# SGX530 register map
Vendor: Texas Instruments
Registers are 32-bit, read-write, no defined reset value unless marked. A register's access mark holds for its fields unless they carry their own. Offsets are as the file gives them; [hi:lo] are bit positions; {n}, {i} and the like mark numbered series; 'fields as' and 'values as' point back to an identical list.

## SGX530 (part 2 of 2)
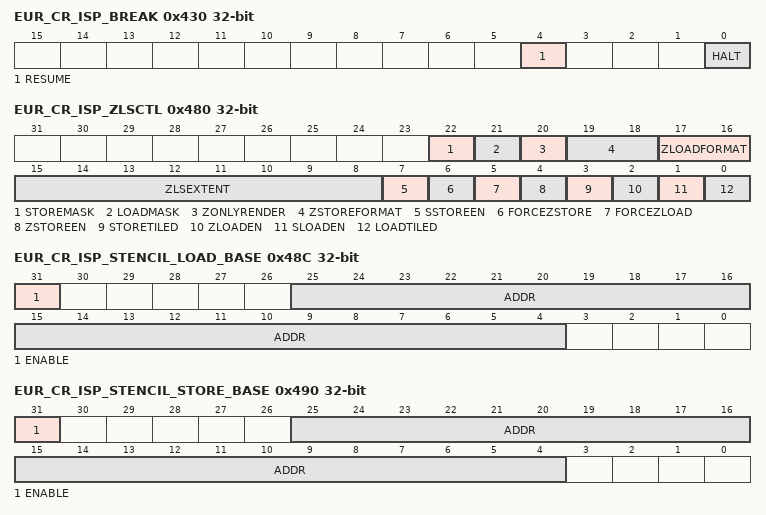
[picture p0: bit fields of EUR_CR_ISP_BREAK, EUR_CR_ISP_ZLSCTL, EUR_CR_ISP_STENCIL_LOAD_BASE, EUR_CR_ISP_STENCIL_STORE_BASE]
0x430 EUR_CR_ISP_BREAK wo — Object breakpoints can be inserted by the driver to interrupt a render part way and then resume the render from the point of interrupt at a later time, this register controls what happens when a breakpoint has been encountered.
  [4] RESUME — Resumes the current render after a breakpoint object is encountered in the internal parameter stream
  [0] HALT — Terminates the current render after a breakpoint object is encountered in the internal parameter stream
0x434 EUR_CR_ISP_3DCONTEXT wo
  [0] ENABLE — ISP Context Store, any write to this register will cause the ISP to halt processing new primitives, insert an end of render command and wait for the current primitives in the pipeline to complete processing up to the inserted end of render.
0x438 EUR_CR_ISP_FPU ro
  [31:0] SIGNATURE — ISP FPU signature result. A signature is an accumulative LFSR (Linear Feedback Shift Register) of the valid pipeline data using an XOR structure.
0x43C EUR_CR_TSP_PARAMETER_CACHE wo
  [0] INVALIDATE — Any write to this register will invalidate the Content Addressable Memory in the TSP parameter fetch cache
0x440 EUR_CR_TSP_PARAMETER_FETCH
  [1:0] TTE_SCALE — Scale factor for TSP parameter fetch to BIF TTE.
0x480 EUR_CR_ISP_ZLSCTL — Image Synthesis Processor Z Load/Store & format global control register
  [22] STOREMASK — This bit modifies the behaviour when ISP_ZLSCTL:[ZSTOREFORMAT] = 0x0. 0 - Binary 0 is stored in place of the current rendered mask plane. All stored Z values will appear in memory as positive IEEE floats; 1 - The mask plane is stored per pixel location a rendered to the on-chip tile buffer and occupies the MSB (sign bit) of all IEEE float dwords
  [21] LOADMASK — This bit modifies the behaviour when ISP_ZLSCTL:[ZLOADFORMAT] = 0x0. 0 - The entire tile will be loaded with the mask plane value as determined by ISP_BGOBJ:[MASK]; 1 - The mask plane is loaded exactly as it appears in memory with the mask plane bit in the MSB (sign bit) of each loaded IEEE float formatted dword
  [20] ZONLYRENDER — When set, only the Z buffer is rendered. Opaque and translucent objects are stencil and depth tested as usual but no pixel spans are emitted to the PDS Pixel presenter. Pixels within punch through and depth feedback objects are emitted on their first pass as a result of passing the up-front depth test by default. However, on their feedback depth test, these pixels will not be output regardless of the depth test result. The intention is to calculate a scene Z buffer without doing any further rendering.
  [19:18] ZSTOREFORMAT — Selects the format depth, stencil and viewport is stored in: 0x0 32 bit IEEE SP Float; 0x1 24 bit Integer + 8-bit Stencil; 0x2 Two 16 bit Integers (Packed format); 0x3 32-bit IEEE Float 8-bit Stencil 1-bit Viewport Compressed, addressed using DPM
  [17:16] ZLOADFORMAT — Selects the format depth, stencil and viewport is stored in: 0x0 32 bit IEEE SP Float; 0x1 24 bit Integer + 8-bit Stencil; 0x2 Two 16 bit Integers (Packed format); 0x3 32-bit IEEE Float 8-bit Stencil 1-bit Viewport Compressed, addressed using DPM
  [15:8] ZLSEXTENT — Display width in tiles (16 pixels) minus one: 0x00 1 tile (16 pixels) 0x01 2 tiles (32 pixels) .. 0xFF 256 tiles (4096 pixels)
  [7] SSTOREEN — When set to 1, if the ZSTORE bit in the region header is also set then the stencil buffer is stored to memory after each tile is processed
  [6] FORCEZSTORE — If set to 1 the depth/stencil buffer is always stored at the end of each tile irrespective of the region header ZSTORE bit.
  [5] FORCEZLOAD — If set to 1 the depth/stencil buffer is always loaded at the start of each tile irrespective of the region header ZLOAD bit.
  [4] ZSTOREEN — When set to 1, if the ZSTORE bit in the region header is also set then the depth buffer is stored to memory after each tile is processed
  [3] STORETILED — When set to 1 depth and stencil data is written out in "Tiled" order. (Note: Data can not be written as tiled, if the ZSTOREFORMAT = 0x3. In this case STORETILED should be set to ‘0’)
  [2] ZLOADEN — When set to 1, if the ZLOAD bit in the region header is also set then the depth buffer is read from memory prior to tile processing
  [1] SLOADEN — When set to 1, if the ZLOAD bit in the region header is also set then the stencil buffer is read from memory prior to tile processing
  [0] LOADTILED — When set to 1 depth, stencil data is loaded in "Tiled" order (Note: Data can not be read as tiled, if the ZSTOREFORMAT = 0x3. In this case LOADTILED should be set to ‘0’)
0x484 EUR_CR_ISP_ZLOAD_BASE — This register defines the base address in memory of the Z Buffer base address to load into the ISP for non-compressed ZLS formats.
  [25:4] ADDR — 64MB Addressable, 16byte aligned Base Address of the Z Buffer Load base address
0x488 EUR_CR_ISP_ZSTORE_BASE — This register defines the base address in memory of the Z Buffer base address to store data from the ISP for non-compressed ZLS formats.
  fields as EUR_CR_ISP_ZLOAD_BASE
0x48C EUR_CR_ISP_STENCIL_LOAD_BASE — This register defines the base address in memory of the Stencil Buffer base address to load into the ISP for Int24 and IEEE ZLS formats. This alternate stencil buffer base address is selectable based on the enable bit.
  [31] ENABLE — When set to 1, enables fetching of stencil from a separate base address
  [25:4] ADDR — 64MB Addressable, 16byte aligned Base Address of the Stencil Buffer Load base address
0x490 EUR_CR_ISP_STENCIL_STORE_BASE — This register defines the base address in memory of the Stencil Buffer base address to store data from the ISP for Int24 and IEEE ZLS formats. This alternate stencil buffer base address is selectable based on the enable bit.
  [31] ENABLE — When set to 1, enables saving of stencil to a separate base address
  [25:4] ADDR — 64MB Addressable, 16byte aligned Base Address of the Stencil Buffer Load base address
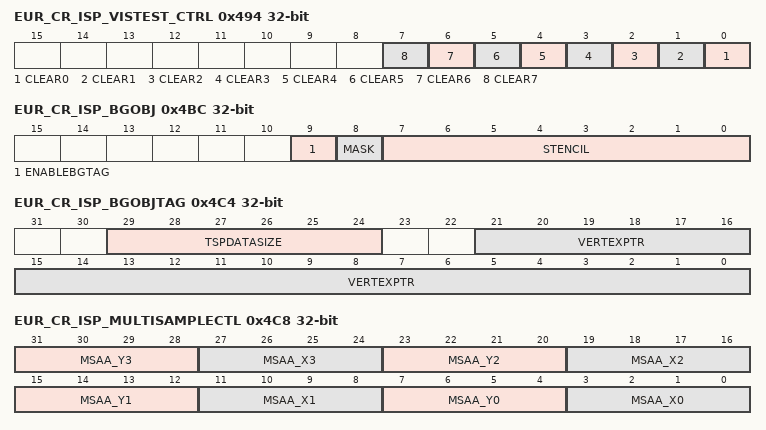
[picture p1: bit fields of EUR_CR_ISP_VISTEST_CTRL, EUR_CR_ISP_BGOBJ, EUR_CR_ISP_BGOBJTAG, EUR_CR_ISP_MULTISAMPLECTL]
0x494 EUR_CR_ISP_VISTEST_CTRL wo — This register can be used to reset the results of the 8 visibility test results. Write a 1 to the required bit field to clear the result register
  [n] CLEAR{n} (n=0..7) — Resets Visibility Test register {n}
{0x498+4i} EUR_CR_ISP_VISTEST_VISIBLE{i} ro (i=0..7)
  [31:0] COUNT — Visibility Test counter {i}
0x4B8 EUR_CR_ISP_BGOBJDEPTH — The ISP operates by comparing depth values of incoming objects with the results of previous depth compares, in order to make sure there are no un-initialised values at the start of the tile or to cover pixels where there are no objects in the scene a default background object is configured under register control. This register provides the floating point depth value for this background object.
  [31:0] VALUE — Hardware background object depth value in 32 bit IEEE single precision floating point format
0x4BC EUR_CR_ISP_BGOBJ — The ISP operates by comparing depth values of incoming objects with the results of previous depth compares, in order to make sure there is no un-initialised values at the start of the tile or to cover pixels where there are no objects in the scene a default background object is configured under register control. This register provides tag, mask and stencil information for this background object.
  [9] ENABLEBGTAG — When set to 1, at the start of each tile the ISP tag buffer is initialised with the background object tag (default = 1)
  [8] MASK — Hardware background object mask plane
  [7:0] STENCIL — Hardware background object stencil
0x4C4 EUR_CR_ISP_BGOBJTAG — The ISP operates by comparing depth values of incoming objects with the results of previous depth compares, in order to make sure there are no unitialised values at the start of the tile or to cover pixels where there are no objects in the scene a default background object is configured under register control. This register provides TSP and Vertex information for this background object.
  [29:24] TSPDATASIZE — Hardware background object TSP data size in dwords
  [21:0] VERTEXPTR — Bits 25:4 of the hardware background object vertex pointer (64MB range on 16 byte boundaries)
0x4C8 EUR_CR_ISP_MULTISAMPLECTL — This applies when anti-aliasing is enabled. This is used by the ISP to adjust the sample positions.
  [31:28] MSAA_Y3 — Unsigned sub-pixel offset for the 4th multisample Y position
  [27:24] MSAA_X3 — Unsigned sub-pixel offset for the 4th multisample X position
  [23:20] MSAA_Y2 — Unsigned sub-pixel offset for the 3rd multisample Y position
  [19:16] MSAA_X2 — Unsigned sub-pixel offset for the 3rd multisample X position
  [15:12] MSAA_Y1 — Unsigned sub-pixel offset for the 2nd multisample Y position
  [11:8] MSAA_X1 — Unsigned sub-pixel offset for the 2nd multisample X position
  [7:4] MSAA_Y0 — Unsigned sub-pixel offset for the 1st multisample Y position
  [3:0] MSAA_X0 — Unsigned sub-pixel offset for the 1st multisample X position
0x4CC EUR_CR_ISP_SIG1 ro
  [31:0] PRECALC — Signature analysis - face equation precalc. A signature is an accumulative LFSR (Linear Feedback Shift Register) of the valid pipeline data using an XOR structure.
0x4D0 EUR_CR_ISP_SIG2 ro
  [31:0] EDGE — Signature analysis - edge processors. A signature is an accumulative LFSR (Linear Feedback Shift Register) of the valid pipeline data using an XOR structure.
0x4D4 EUR_CR_ISP_SIG3 ro
  [31:0] TAGWRITE — Signature analysis - state buffer storage. A signature is an accumulative LFSR (Linear Feedback Shift Register) of the valid pipeline data using an XOR structure.
0x4D8 EUR_CR_ISP_SIG4 ro
  [31:0] SPAN — Signature analysis - spans to PDS pixel presenter. A signature is an accumulative LFSR (Linear Feedback Shift Register) of the valid pipeline data using an XOR structure.
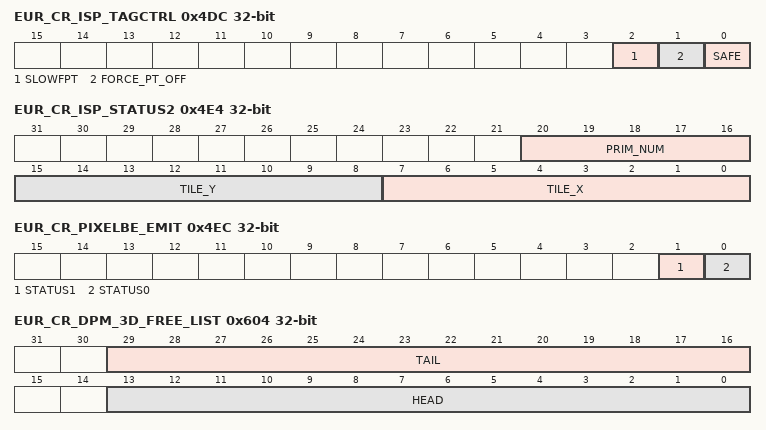
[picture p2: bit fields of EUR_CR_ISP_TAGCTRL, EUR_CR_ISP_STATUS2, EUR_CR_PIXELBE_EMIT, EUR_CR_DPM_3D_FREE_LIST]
0x4DC EUR_CR_ISP_TAGCTRL
  [2] SLOWFPT — Debug punchthrough, converts fast punchthrough to normal punchthrough
  [1] FORCE_PT_OFF — Debug punchthrough mode which forces pt_off after every pt,dfb and fpt triangle
  [0] SAFE — Safe flush mode, pass-spawn flushes for every translucent object
0x4E0 EUR_CR_ISP_STATUS1 ro
  [25:2] CTRL_STREAM_POS — Control Stream Position after context switch
0x4E4 EUR_CR_ISP_STATUS2 ro
  [20:16] PRIM_NUM — Position of current primitive after context switch
  [15:8] TILE_Y — Tile Y coordinate after context switch
  [7:0] TILE_X — Tile X coordinate after context switch
0x4E8 EUR_CR_ISP_DEPTHSORT
  [0] DETERMINISTIC — deterministic mode for depth sorter
0x4EC EUR_CR_PIXELBE_EMIT ro — This register indicates if the PixelBE would stall the USE if there were another emit. '1' indicates that the PixelBE would stall the USE. '0' indicates that the PixelBE would not stall the USE.
  [1] STATUS1 — Pipe 1 status
  [0] STATUS0 — Pipe 0 status
0x600 EUR_CR_DPM_3D_PAGE_TABLE_BASE — Effective on load 3D context, this register defines the base address of the page table being referenced in the process of de-allocating pages during a 3D render.
  [27:4] ADDR — 256MB Addressable, 16Byte aligned Base Address for 3D context page tables in the DPM module
0x604 EUR_CR_DPM_3D_FREE_LIST — Between the FREE_LIST_HEAD and FREE_LIST_TAIL there must be a valid chain of linked pages. The linked list is stored in memory, at the EUR_CR_DPM_3D_PAGE_TABLE_BASE_ADDRESS and is effective on load 3D context.
  [29:16] TAIL — This register defines the last page to be used for the 3D page allocation, on a load 3D context. (The tail of the free list.)
  [13:0] HEAD — This register defines the first page to be used for the 3D page allocation, on a load 3D context.
0x614 EUR_CR_DPM_PDS_PAGE_THRESHOLD — This is the threshold in 4KB pages at which the hardware will stop double buffering the internal vertex processing buffers (and drop to single buffered mode). This is required in order to guarantee that a 3D render can run when running in dynamic parameter management mode. It should be set to 0.25MB less (in pages 0x40) than the ZLS threshold (or 0 in very small memory systems).
  [13:0] VALUE — Page Threshold at which vertex buffers stop being double buffered
0x618 EUR_CR_DPM_TA_ALLOC_PAGE_TABLE_BASE — Effective on Loading the TA Page Table Context, this register defines the base address of the page table being referenced in the process of allocating pages by the TE and MTE.
  [27:4] ADDR — 256MB Addressable, 16Byte aligned Base Address for TE/MTE context page tables in the DPM module.
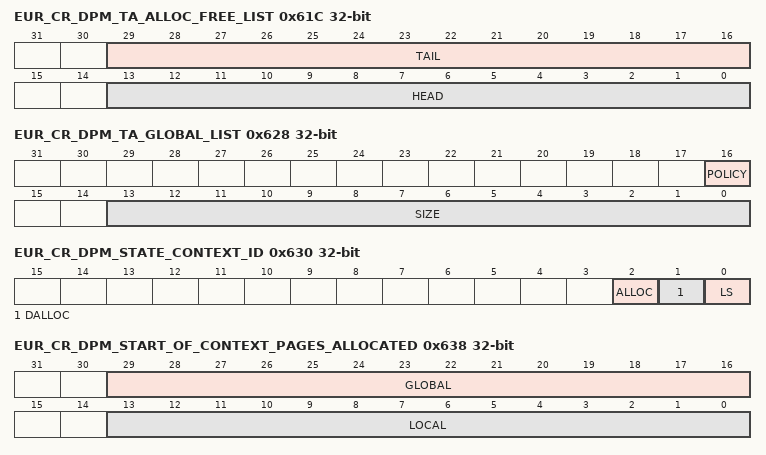
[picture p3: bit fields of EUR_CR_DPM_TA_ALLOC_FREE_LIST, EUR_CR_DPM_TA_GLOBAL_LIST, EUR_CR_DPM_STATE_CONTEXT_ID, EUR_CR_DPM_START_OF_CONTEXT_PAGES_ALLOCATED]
0x61C EUR_CR_DPM_TA_ALLOC_FREE_LIST — Between the FREE_LIST_HEAD and FREE_LIST_TAIL there must be a valid chain of linked pages. The linked list is stored in memory, at the EUR_CR_DPM_TA_ALLOC_PAGE_TABLE_BASE_ADDRESS and is effective on Loading the TA Page Table Context.
  [29:16] TAIL — This register defines the last page for the free list manipulated during TE and MTE page allocation
  [13:0] HEAD — This register defines the start page for the free list manipulated during TE and MTE page allocation
0x620 EUR_CR_DPM_TA_PAGE_THRESHOLD
  [13:0] VALUE — Effective on Loading the TA Page Table Context, the maximum number of pages to allocate before signaling almost out of memory.
0x624 EUR_CR_DPM_ZLS_PAGE_THRESHOLD
  [13:0] VALUE — Effective on Loading the TA Page Table Context, the maximum number of pages to allocate before signaling out of memory to the host. The ZLS threshold should be set such that sufficient pages are left available to the ZLS module when it performs its dynamic memory allocation upon a partial render. The number of pages spare should be set to be larger than the maximum pages for 1 macro tile of Z data. For example: If 4 pages are required for 1 macro tile of Z, and there are 50 pages in the system, then this threshold should be set to 50 - 4 = 46.
0x628 EUR_CR_DPM_TA_GLOBAL_LIST
  [16] POLICY — Effective on Loading the TA Page Table Context, a value of 1 in this field enables the global list size limit
  [13:0] SIZE — Effective on Loading the TA Page Table Context, the maximum number of pages to allocate to the global list before signaling global list out of memory.
0x62C EUR_CR_DPM_STATE_TABLE_BASE — Effective immediately, this register defines the base address of the state table when it is read and written to/from memory. The state table itself contains the head, tail and number of pages allocated to every macrotile, and the global list. Each context needs a separate state page table.
  [27:4] ADDR — 256MB Addressable, 16Byte aligned Base Address for State Table in the DPM module.
0x630 EUR_CR_DPM_STATE_CONTEXT_ID
  [2] ALLOC — Effective immediately, this field defines the which of the internal contexts is to be used for allocating memory
  [1] DALLOC — Effective immediately, this field defines the which of the internal contexts is to be used for de-allocating memory
  [0] LS — Effective immediately, this field defines which of the internal contexts is to be loaded or stored from/to memory
0x634 EUR_CR_DPM_CONTROL_TABLE_BASE — Effective immediately, this register defines the base address of the control table when it is read and written to/from memory. The control table itself contains the current offset into the page, and whether a page has been allocated, for each macrotile. Each context needs a separate state page table.
  [27:4] ADDR — 256MB Addressable, 16Byte aligned Base Address for the Control Table in the DPM module.
0x638 EUR_CR_DPM_START_OF_CONTEXT_PAGES_ALLOCATED
  [29:16] GLOBAL — Effective on the loading of the TA Page Table Context, this register defines the number of the pages which are currently allocated to the context global list. The value for this register is read from the matching status register, on a context store, and loaded on a context load.
  [13:0] LOCAL — Effective on the loading of the TA Page Table Context, this register defines the number of the pages which are currently allocated to the context. The value for this register is read from the matching status register, on a context store, and loaded on a context load.
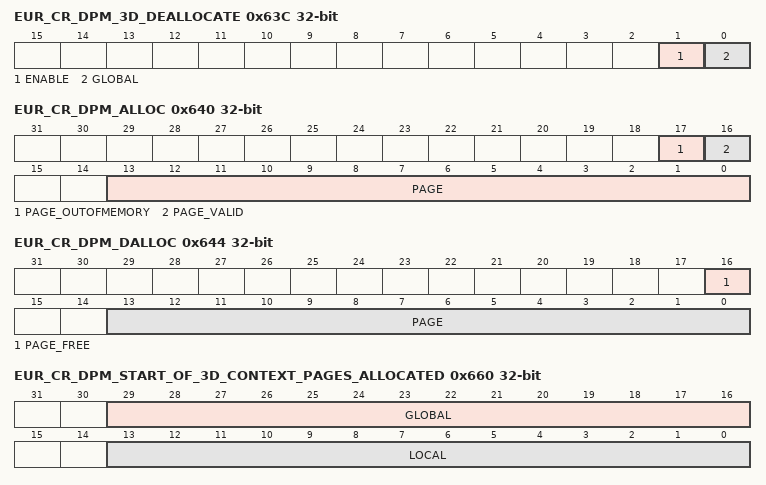
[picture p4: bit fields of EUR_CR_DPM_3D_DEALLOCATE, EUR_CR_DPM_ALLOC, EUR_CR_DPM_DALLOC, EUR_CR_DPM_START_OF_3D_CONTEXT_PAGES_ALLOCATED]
0x63C EUR_CR_DPM_3D_DEALLOCATE
  [1] ENABLE — Effective on start render, this field indicates that the hardware should de-allocate Effective on start render, this field indicates that the hardware should de-allocate memory.mory.
  [0] GLOBAL — Effective on start render, this field indicates that the hardware should de-allocate the memory associated with the global list if it is set.
0x640 EUR_CR_DPM_ALLOC — A write to this register invalidates the current contents and causes a new allocation cycle
  [17] PAGE_OUTOFMEMORY — Out of memory. Indicates that the action is pending due to an out of memory condition.
  [16] PAGE_VALID — On a read a value of 1 in this field indicates that the page has been allocated, and that the page is valid.
  [13:0] PAGE — A read of this register returns the page allocated to the host, when valid. If it is not valid the return data is undefined.
0x644 EUR_CR_DPM_DALLOC — A write to this register invalidates the current contents and causes a new de-allocation cycle
  [16] PAGE_FREE — A read indicates whether the page has been freed
  [13:0] PAGE — The page to be de-allocated by the hardware
0x648 EUR_CR_DPM_TA_ALLOC
  [29:16] FREE_LIST_PREVIOUS — Effective on Load TA Page Table Context: TA Alloc Free List Previous Page. The DPM maintains the previous and current free list pointers. On a context load this value must be loaded in. For the initial case it should be set to the penultimate page after initialisation (normally TAIL - 1).
0x64C EUR_CR_DPM_3D
  [29:16] FREE_LIST_PREVIOUS — Effective on Load 3D Page Table Context: 3D Free List Previous Page. The DPM maintains the previous and current free list pointers. On a context load this value must be loaded in. For the initial case it should be set to the penultimate page after initialisation (normally TAIL - 1).
0x658 EUR_CR_DPM_PARTIAL_RENDER
  [0] ENABLE — Once The TA DPM has run out of memory, and the driver has scheduled an abort, there must be a partial render performed on the context in order to free memory. This bit is set before the partial render is started.
0x65C EUR_CR_DPM_LSS_PARTIAL_CONTEXT
  [0] OPERATION — When set indicates that on a Context state table load, reset or store only the best macro tile, rather than the full scene.
0x660 EUR_CR_DPM_START_OF_3D_CONTEXT_PAGES_ALLOCATED
  [29:16] GLOBAL — Effective on the loading of the 3D Page Table Context, this register defines the number of the pages which are currently allocated to the context global list. The value for this register is read from the matching status register, on a context store, and loaded on a context load.
  [13:0] LOCAL — Effective on the loading of the 3D Page Table Context, this register defines the number of the pages which are currently allocated to the context. The value for this register is read from the matching status register, on a context store, and loaded on a context load.
0x680 EUR_CR_DPM_TASK_3D_FREE wo
  [0] LOAD — Causes the 3D free list context to be loaded from the relevant configuration registers
0x684 EUR_CR_DPM_TASK_TA_FREE wo
  [0] LOAD — Causes the TA free list context to be loaded from the relevant configuration registers
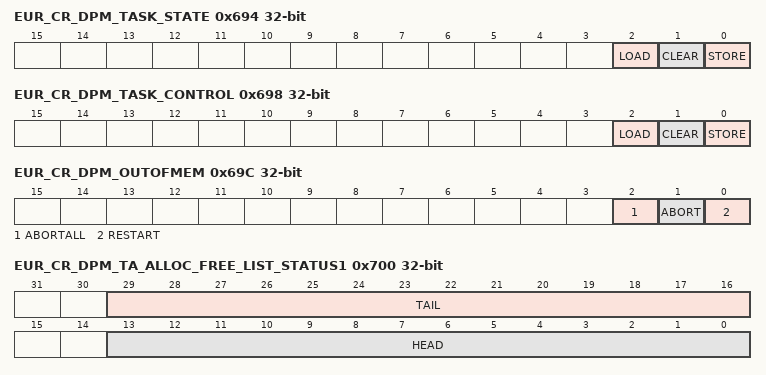
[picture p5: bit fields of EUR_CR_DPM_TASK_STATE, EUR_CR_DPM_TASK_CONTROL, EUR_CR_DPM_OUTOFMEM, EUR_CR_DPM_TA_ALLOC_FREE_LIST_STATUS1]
0x694 EUR_CR_DPM_TASK_STATE wo — This register controls the DPM module task state for page tables. The normal order of operation is Store context, Clear context, Load new context.
  [2] LOAD — Causes the state for the DPM page table to be read from memory. Only the selected context ID is loaded.
  [1] CLEAR — Causes the state for the DPM page table to be cleared. Only the selected context ID is cleared.
  [0] STORE — Causes the state for the DPM page table (non-destructive - the state is not cleared as it is written) to be written to memory. Only the selected context ID is written out.
0x698 EUR_CR_DPM_TASK_CONTROL wo — This register controls the DPM module task state for control page tables. The normal order of operation is Store context, Clear context, Load new context.
  [2] LOAD — Causes the state for the control page table to be read from memory.
  [1] CLEAR — Causes the state for the control page table to be cleared.
  [0] STORE — Causes the state for the control table (non-destructive - the control is not cleared as it is written) to be written to memory.
0x69C EUR_CR_DPM_OUTOFMEM wo
  [2] ABORTALL — Causes the hardware to initiate the abort cycle, resulting in an abort complete, and requiring a subsequent full render, in the order of busiest to least busy macro tile. The region headers need to be re-ordered by the driver to guarantee this condition
  [1] ABORT — Causes the hardware to initiate the abort cycle, resulting in an abort complete, and requiring a subsequent partial render
  [0] RESTART — Causes the parameter management to resume trying to allocate pages
0x6A0 EUR_CR_DPM_FREE_CONTEXT wo
  [0] NOW — Causes the hardware to free the memory associated with the current TA context
0x6A4 EUR_CR_DPM_3D_TIMEOUT wo
  [0] NOW — Causes the hardware to free the memory associated with the current 3D context, and if a render is in progress, treat this as if it were complete.
0x6A8 EUR_CR_DPM_TA_EVM wo
  [0] INIT — Initialise the TA linked list (between start and end only), to an area of linear memory
0x700 EUR_CR_DPM_TA_ALLOC_FREE_LIST_STATUS1 ro — This status register is read for a context switch, and reprogrammed on a context load.
  [29:16] TAIL — The current tail of the free list for the TA allocation context
  [13:0] HEAD — The current head of the free list for the TA allocation context
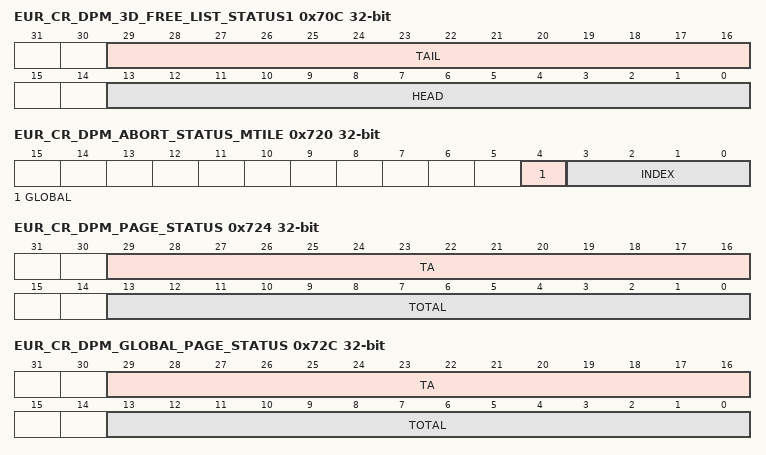
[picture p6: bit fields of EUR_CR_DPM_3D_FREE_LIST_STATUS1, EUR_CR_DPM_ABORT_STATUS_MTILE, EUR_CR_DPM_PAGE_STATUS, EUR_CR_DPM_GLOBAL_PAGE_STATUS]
0x70C EUR_CR_DPM_3D_FREE_LIST_STATUS1 ro — This status register is read for a context switch, and reprogrammed on a context load.
  [29:16] TAIL — The current tail of the free list for the 3D context
  [13:0] HEAD — The current head of the free list for the 3D context
0x710 EUR_CR_DPM_TA_ALLOC_FREE_LIST_STATUS2 ro — This status register is read for a context switch, and reprogrammed on a context load.
  [13:0] PREVIOUS — The element before the tail of the free list for the TA allocation context
0x71C EUR_CR_DPM_3D_FREE_LIST_STATUS2 ro — This status register is read for a context switch, and reprogrammed on a context load.
  [13:0] PREVIOUS — The element before the tail of the free list for the 3D context
0x720 EUR_CR_DPM_ABORT_STATUS_MTILE ro — This status register is read for a context switch, and reprogrammed on a context load.
  [4] GLOBAL — Indicates that the whole scene must be aborted
  [3:0] INDEX — The macro tile which will be aborted by the hardware
0x724 EUR_CR_DPM_PAGE_STATUS ro — This status register is read for a context switch, and reprogrammed on a context load.
  [29:16] TA — The number of pages allocated by the hardware, for the TA context
  [13:0] TOTAL — The total number of pages allocated by the hardware, across all contexts
0x728 EUR_CR_DPM_PAGE ro — This status register is read for a context switch, and reprogrammed on a context load.
  [13:0] STATUS_3D — The number of pages allocated by the hardware, for the 3D context
0x72C EUR_CR_DPM_GLOBAL_PAGE_STATUS ro — This status register is read for a context switch, and reprogrammed on a context load.
  [29:16] TA — The number of global pages allocated by the hardware, for the TA context
  [13:0] TOTAL — The total number of global pages allocated by the hardware, across all contexts
0x730 EUR_CR_DPM_GLOBAL_PAGE ro — This status register is read for a context switch, and reprogrammed on a context load.
  [13:0] STATUS_3D — The total number of global pages allocated by the hardware, across the 3D contexts
0x734 EUR_CR_DPM_REQUESTING ro
  [1:0] SOURCE — The device that is requesting memory; Bit 0 is the TA (Control Stream Request), Bit 1 is the TA (Vertex Data Stream Request)
0x738 EUR_CR_DPM_RNG_HDR_PARSER ro
  [0] IDLE — The DPM Region Header IDLE indication, ‘1’ = idle, ‘0’ = busy
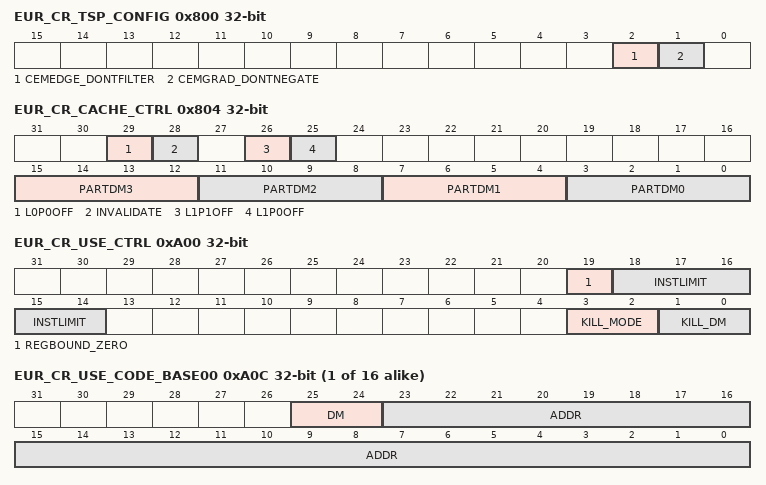
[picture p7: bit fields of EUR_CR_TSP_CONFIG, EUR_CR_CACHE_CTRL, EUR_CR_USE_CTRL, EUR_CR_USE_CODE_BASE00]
0x800 EUR_CR_TSP_CONFIG
  [2] CEMEDGE_DONTFILTER — Disable filtering over edges/corners for CEM
  [1] CEMGRAD_DONTNEGATE — Disable negation for user supplied gradients for cem swap i.e. will only swap dudx etc not negate
0x804 EUR_CR_CACHE_CTRL — Unified Cache global control register
  [29] L0P0OFF — Cache L0 Pipe1 Bypass
  [28] INVALIDATE — Cache Invalidate - To invalidate the cache, ie remove all contents from the cache, then setting this bit to 1 will start an invalidation cycle within the cache. Immediately the cache will not except anymore read request until the invalidation cycle completes. All requests pending in the cache (L0/L1/L2) will be completed before the cache completes its invalidation cycle. On completion of the invalidation cycle an interrupt will occur, if enabled, and the MADD_CACHE_INVALCOMP bit will be set and the cache will return to its normal operation
  [26] L1P1OFF — Cache Off L1 Pipe1 - When set to 1 turns off the L1 cache associated with Pipe 1. Read request to the L1 cache will be forwarded directly to the L2 cache. The cache must be invalidated after the bit is set to 0 (Cache Level On)
  [25] L1P0OFF — Cache Off L1 Pipe0 - When set to 1 turns off the L1 cache associated with Pipe 0. Read request to the L1 cache will be forwarded directly to the L2 cache. The cache must be invalidated after the bit is set to 0 (Cache Level On)
  [15:12] PARTDM3 — Cache Partition Mask for DM3 - defines which cache lines are used for Data Master type 3. Each bit represents one cache line, where there are 4 cache lines in the cache. Each cache line contains 8 possible address tags which are compared against the incoming address to determine if the data requested is in the cache or not. If all bits are set then there are 4 x 8 possible address tags i.e. DM3 read request will try and match against all the cache ram contents. Setting a bit to 0, will exclude that cache line from being compared against the incoming request address
  [11:8] PARTDM2 — Cache Partition Mask for DM2 - Refer to PARTDM3, but with respect to DM2
  [7:4] PARTDM1 — Cache Partition Mask for DM1 - Refer to PARTDM3, but with respect to DM1
  [3:0] PARTDM0 — Cache Partition Mask for DM0 - Refer to PARTDM3, but with respect to DM0
0xA00 EUR_CR_USE_CTRL
  [19] REGBOUND_ZERO — 0: RETURN_ONE Controls whether out-of-range indexed-mode MOE register numbers redirect to 0 for alpha (when set) or 1 (when cleared) 0 RETURN_ONE 1 RETURN_ZERO
  [18:14] INSTLIMIT — Maximum number of times an active slot can be serviced in a row
  [3:2] KILL_MODE — 0x0 Off
    1=Flush; 2=Kill
  [1:0] KILL_DM — Data master to kill
0xA04 EUR_CR_USE_LD_REDIRECT
  [31:4] ADDR — Byte-aligned memory address to redirect LD instructions which fail range check
0xA08 EUR_CR_USE_CACHE wo
  [0] INVALIDATE — Any write to this location invalidates the instruction cache automatically
{0xA0C+4i} EUR_CR_USE_CODE_BASE{i:02} wo (i=0..15)
  [25:24] DM — Data Master
  [23:0] ADDR — Code Base Address
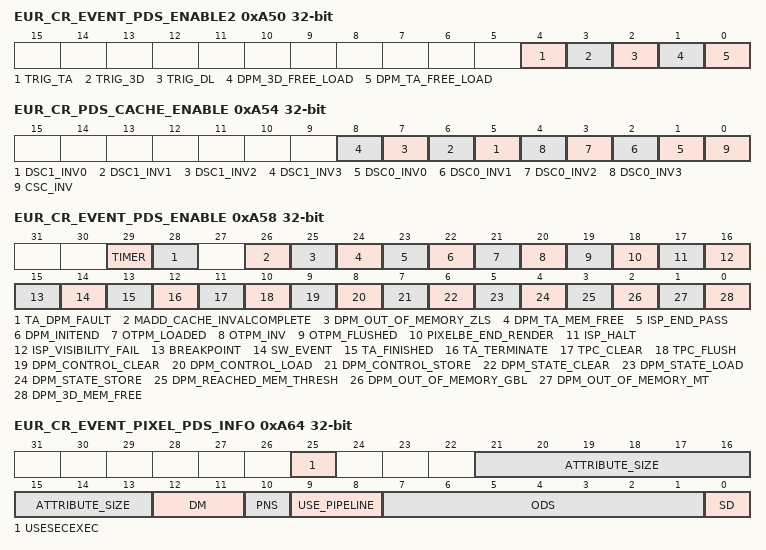
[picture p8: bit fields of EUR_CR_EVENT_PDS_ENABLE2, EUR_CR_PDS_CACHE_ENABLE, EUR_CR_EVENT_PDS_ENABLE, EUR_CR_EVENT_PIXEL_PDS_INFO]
0xA50 EUR_CR_EVENT_PDS_ENABLE2 — Enables general event bits into the PDS event data master for processing by the PDS Micro Controller
  [4] TRIG_TA — PDS_Enable: Lockup in TA Phase Trigger
  [3] TRIG_3D — PDS_Enable: Lockup in 3d Phase Trigger
  [2] TRIG_DL — PDS_Enable: Deadlock has occurred after a Partial Render
  [1] DPM_3D_FREE_LOAD — PDS_Enable: DPM 3D Task free load complete
  [0] DPM_TA_FREE_LOAD — PDS_Enable: DPM TA Task free load complete
0xA54 EUR_CR_PDS_CACHE_ENABLE — Enables PDS cache invalidation events bits into the PDS event data master for processing by the PDS Micro Controller
  [n+5] DSC1_INV{n} (n=0..3) — PDS_Enable: Context ID {n} has been invalidated in PDS Data Store Cache 1
  [n+1] DSC0_INV{n} (n=0..3) — PDS_Enable: Context ID {n} has been invalidated in PDS Data Store Cache 0
  [0] CSC_INV — PDS_Enable: PDS Code Store Cache has been invalidated
0xA58 EUR_CR_EVENT_PDS_ENABLE — Enables general event bits into the PDS event data master for processing by the PDS Micro Controller
  [29] TIMER — PDS_Enable: The PDS Event timer interrupt (signalled on timer traversing through 0).
  [28] TA_DPM_FAULT — PDS_Enable: The TA Object Passing System has got out of sync, a Terminate Control Word DPM read was met by StartofBlock data
  [26] MADD_CACHE_INVALCOMPLETE — PDS_Enable: Invalidate of Madd L0, L1, L2 Cache Complete
  [25] DPM_OUT_OF_MEMORY_ZLS — PDS_Enable: Memory Allocation Failed for ZLS
  [24] DPM_TA_MEM_FREE — PDS_Enable: All memory associated with TA context has been freed
  [23] ISP_END_PASS — PDS_Enable: ISP End pass
  [22] DPM_INITEND — PDS_Enable: DPM Initialisation Complete
  [21] OTPM_LOADED — PDS_Enable: The OTPM has loaded its state
  [20] OTPM_INV — PDS_Enable: The OTPM has invalidated its contents
  [19] OTPM_FLUSHED — PDS_Enable: The OTPM has flushed its state
  [18] PIXELBE_END_RENDER — PDS_Enable: End of Scene
  [17] ISP_HALT — PDS_Enable: ISP Halt breakpoint triggered
  [16] ISP_VISIBILITY_FAIL — PDS_Enable: Visibility Test Fail
  [15] BREAKPOINT — PDS_Enable: ISP Breakpoint
  [14] SW_EVENT — PDS_Enable: Software triggered event
  [13] TA_FINISHED — PDS_Enable: TA complete, (Scene Terminated)
  [12] TA_TERMINATE — PDS_Enable: The TA terminate complete (issue as part of complex scene) (MacroTile aborted)
  [11] TPC_CLEAR — PDS_Enable: The TPC has reset its state
  [10] TPC_FLUSH — PDS_Enable: The TPC has stored its state
  [9] DPM_CONTROL_CLEAR — PDS_Enable: The reset of the DPM control context has been completed
  [8] DPM_CONTROL_LOAD — PDS_Enable: The load of the DPM control context has been completed
  [7] DPM_CONTROL_STORE — PDS_Enable: The store of the DPM control context has been completed
  [6] DPM_STATE_CLEAR — PDS_Enable: The reset of the DPM state context has been completed
  [5] DPM_STATE_LOAD — PDS_Enable: The load of the DPM state context has been completed
  [4] DPM_STATE_STORE — PDS_Enable: The store of the DPM state context has been completed
  [3] DPM_REACHED_MEM_THRESH — PDS_Enable: DPM Memory allocation has reached the preset memory threshold for total memory allocation
  [2] DPM_OUT_OF_MEMORY_GBL — PDS_Enable: DPM Memory allocation failed for the global list
  [1] DPM_OUT_OF_MEMORY_MT — PDS_Enable: DPM Memory allocation failed for a macro tile
  [0] DPM_3D_MEM_FREE — PDS_Enable: DPM Memory allocation complete for the current render
0xA5C EUR_CR_EVENT_PIXEL_PDS_EXEC
  [25:4] ADDR — PDS Execution Address for pixel tasks (Positioned as a byte address, 128 bit granularity)
0xA60 EUR_CR_EVENT_PIXEL_PDS_DATA
  [5:0] SIZE — PDS Data Size in 128 bit words, Pixel Tasks
0xA64 EUR_CR_EVENT_PIXEL_PDS_INFO
  [25] USESECEXEC — Secondary tasks should execute on the USSE
  [21:13] ATTRIBUTE_SIZE — The attribute size in 128 bit words
  [12:11] DM — The attribute size in 128 bit words
    0=Vertex; 1=Pixel; 3=Event
  [10] PNS — Allocate primary not secondary memory
  [9:8] USE_PIPELINE — Selects the USSE pipeline allocated to the data master
    0=Data master selects the USSE pipeline; 1=PIPE0; 2=PIPE1; 3=Pipes 0 & 1
  [7:1] ODS — The output data stride in 128 bit words
  [0] SD — Sequential Dependency bit. All end of tile tasks should set this bit, in order to ensure that preceding pixel tasks complete before the tile is emitted.
0xA68 EUR_CR_EVENT_OTHER_PDS_EXEC
  fields as EUR_CR_EVENT_PIXEL_PDS_EXEC
0xA6C EUR_CR_EVENT_OTHER_PDS_DATA
  [5:0] SIZE — PDS Data Size in 128 bit words, Pixel Tasks
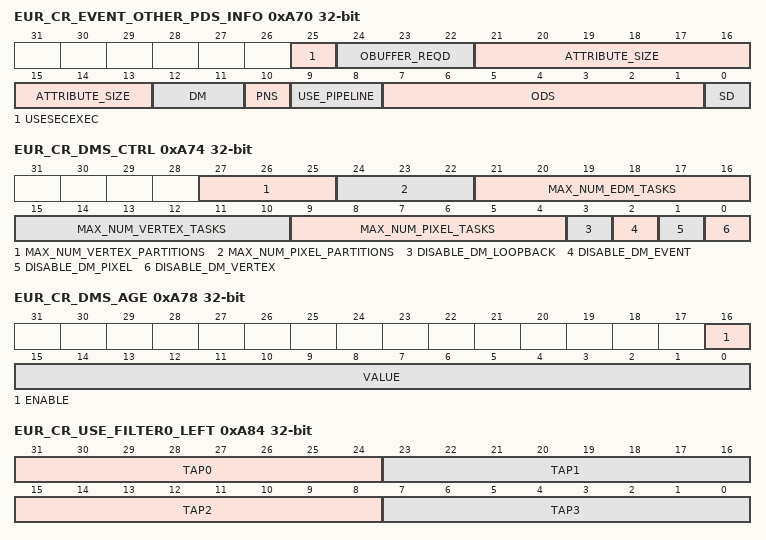
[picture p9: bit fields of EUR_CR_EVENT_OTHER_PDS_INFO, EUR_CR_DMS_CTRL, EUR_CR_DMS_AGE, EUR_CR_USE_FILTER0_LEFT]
0xA70 EUR_CR_EVENT_OTHER_PDS_INFO
  [25] USESECEXEC — Secondary tasks should execute on the USSE
  [24:22] OBUFFER_REQD — The number of output buffers to be allocated
  [21:13] ATTRIBUTE_SIZE — The attribute size in 128 bit words
  [12:11] DM — Selects the Data Master
    0=Vertex; 1=Pixel; 3=Event
  [10] PNS — Allocate primary not secondary memory
  [9:8] USE_PIPELINE — Selects the USSE pipeline allocated to the data master
    values as EUR_CR_EVENT_PIXEL_PDS_INFO.USE_PIPELINE
  [7:1] ODS — The output data stride in 128 bit words
  [0] SD — Sequential Dependency bit. All end of tile tasks should set this bit, in order to ensure that preceding pixel tasks complete before the tile is emitted.
0xA74 EUR_CR_DMS_CTRL — Control register used to disable individual data masters - '1' - disable data master, '0' - enable data master
  [27:25] MAX_NUM_VERTEX_PARTITIONS — The maximum number of partitions allowed on each USSE for vertex tasks
  [24:22] MAX_NUM_PIXEL_PARTITIONS — The maximum number of partitions allowed on each USSE for pixel tasks
  [21:16] MAX_NUM_EDM_TASKS — The maximum number of vertex tasks allowed on each USSE, range 0 to 32
  [15:10] MAX_NUM_VERTEX_TASKS — The maximum number of vertex tasks allowed on each USSE, range 0 to 32
  [9:4] MAX_NUM_PIXEL_TASKS — The maximum number of pixel tasks allowed on each USSE, range 0 to 32
  [3] DISABLE_DM_LOOPBACK — Disable Loopback DM
  [2] DISABLE_DM_EVENT — Disable Event DM
  [1] DISABLE_DM_PIXEL — Disable Pixel DM
  [0] DISABLE_DM_VERTEX — Disable Vertex DM
0xA78 EUR_CR_DMS_AGE
  [16] ENABLE — Enable the AGE Control mechanism
  [15:0] VALUE — The maximum age for any task before it will become a a priority to be serviced (in clock cycles)
0xA7C EUR_CR_USE_G0
  [7:0] P — General-purpose, cross-thread-accessible read/write register for USSE programs via the 'special' bank type
0xA80 EUR_CR_USE_G1
  fields as EUR_CR_USE_G0
0xA84 EUR_CR_USE_FILTER0_LEFT
  [31-8n:24-8n] TAP{n} (n=0..3) — FIRH instruction filter option, signed integer
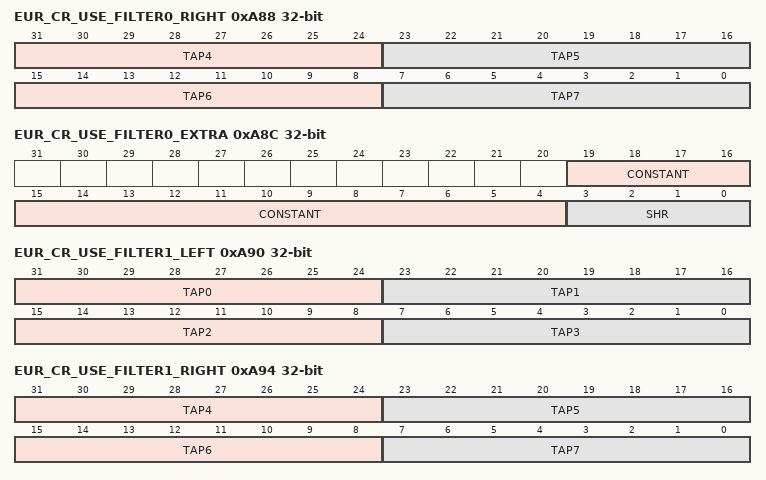
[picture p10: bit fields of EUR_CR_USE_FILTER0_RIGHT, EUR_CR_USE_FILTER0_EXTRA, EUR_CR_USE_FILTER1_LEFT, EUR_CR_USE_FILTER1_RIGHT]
0xA88 EUR_CR_USE_FILTER0_RIGHT
  [63-8n:56-8n] TAP{n} (n=4..7) — FIRH instruction filter option, signed integer
0xA8C EUR_CR_USE_FILTER0_EXTRA
  [19:4] CONSTANT — FIRH instruction filter option, unsigned integer additive constant
  [3:0] SHR — FIRH instruction filter option, unsigned integer right shift amount
0xA90 EUR_CR_USE_FILTER1_LEFT
  fields as EUR_CR_USE_FILTER0_LEFT
0xA94 EUR_CR_USE_FILTER1_RIGHT
  fields as EUR_CR_USE_FILTER0_RIGHT
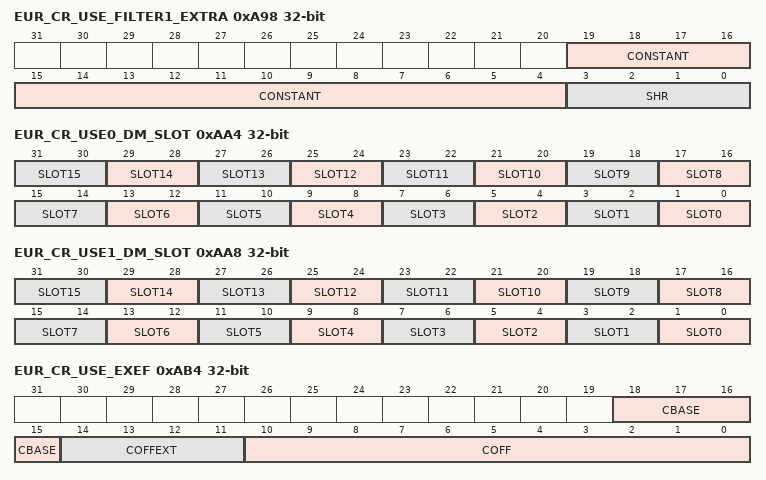
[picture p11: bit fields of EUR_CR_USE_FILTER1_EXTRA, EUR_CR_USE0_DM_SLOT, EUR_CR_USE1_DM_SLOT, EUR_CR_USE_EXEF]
0xA98 EUR_CR_USE_FILTER1_EXTRA
  fields as EUR_CR_USE_FILTER0_EXTRA
0xA9C EUR_CR_USE_FILTER_TABLE
  [1:0] SEL — FIRH instruction filter hardwired-table selector
0xAA0 EUR_CR_USE_ST_RANGE
  [31:0] VALUE — Range check value for ST instruction
0xAA4 EUR_CR_USE0_DM_SLOT ro
  [all] fields
    0=Vertex; 1=Pixel; 2=Empty; 3=Event
  [2n+1:2n] SLOT{n} (n=0..15) — Pipe 0 Data Master in Slot {n}
0xAA8 EUR_CR_USE1_DM_SLOT ro
  fields as EUR_CR_USE0_DM_SLOT
0xAB4 EUR_CR_USE_EXEF
  [18:15] CBASE — Task Flush code baset
  [14:11] COFFEXT — Task Flush code offext
  [10:0] COFF — Task Flush code offset
0xAB8 EUR_CR_PDS_EXEC_BASE — Base Address in memory where the PDS programs are located
  [27:20] ADDR — 256MB Addressable, 1 MB aligned Base Address for PDS programs
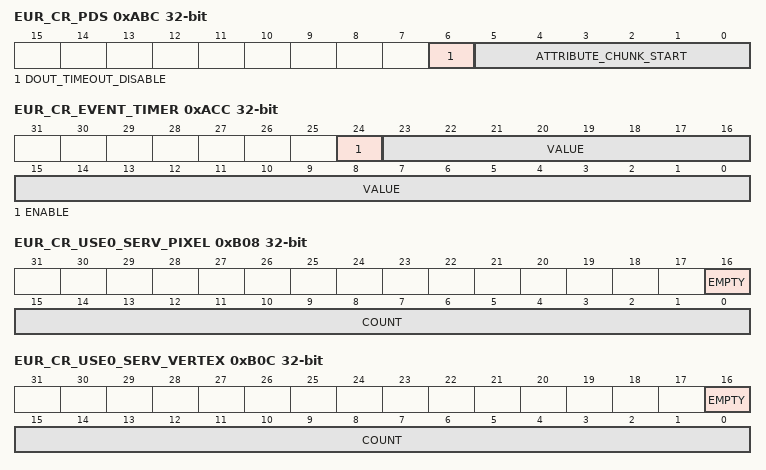
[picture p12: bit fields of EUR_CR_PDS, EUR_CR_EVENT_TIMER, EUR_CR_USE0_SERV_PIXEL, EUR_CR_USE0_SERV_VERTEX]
0xABC EUR_CR_PDS
  [6] DOUT_TIMEOUT_DISABLE — Disable the internal timeout on PDS code performing necessary DOUT commands
  [5:0] ATTRIBUTE_CHUNK_START — The Start Chunk. There are 64 chunks of 32 DWords.
0xAC4 EUR_CR_EVENT_KICKER — Base Address in memory where the Kick Synchronisation data will be read from
  [27:4] ADDRESS — 256MB Addressable, 16Byte aligned Base Address for Kick Synchronisation data
0xAC8 EUR_CR_EVENT_KICK wo
  [0] NOW — The kicker register, a write to this register triggers an increment of the PDS kicker.
0xACC EUR_CR_EVENT_TIMER — The timer which runs at the core clock when enabled, decrementing from the loaded value. Wraps when it hits 0 back to the starting value. A transition through 0 creates an event, which can be enabled into either the PDS or the Host status register. The timer can also be read/written from within the PDS program.
  [24] ENABLE — A value of '1' enables the timer, 0 disables the counter (halts without initialisation to 0).
  [23:0] VALUE — The Starting value for the timer (loaded on write from wither PDS or host).
{0xAD0+4i} EUR_CR_PDS_INV{i} wo (i=0..3)
  [0] DSC — Invalidate Context {i} in PDS Data Store Caches 0 and 1
0xAE0 EUR_CR_PDS_INV_CSC wo
  [0] KICK — Invalidate PDS Code Store Cache
{0xAE4+4i} EUR_CR_USE_GLOBCOM{i} (i=0..7)
  [7:0] COUNT — Counters for cross-thread synchronisation and communication - used for parallelising video processing
0xB04 EUR_CR_LOOPBACK ro — This USE can issue loopback tasks through the PDS back to itself. This bit indicates the status of this interface. A value of 1 should that there are no pending loopback requests (for any USE pipeline), A value of 0 indicates that a loop task is pending, and that further loopback events may cause the USE pipeline to wait until new resource becomes available. Issuing loopback events when tasks are already pending is not recommended, as this may result in system lockups.
  [0] STATUS — The Starting value for the timer (loaded on write from wither PDS or host).
0xB08 EUR_CR_USE0_SERV_PIXEL ro
  [16] EMPTY — No Pixel Data Master tasks in USE0 queue
  [15:0] COUNT — Number of Pixel Data Master tasks serviced by USE0
0xB0C EUR_CR_USE0_SERV_VERTEX ro
  [16] EMPTY — No Vertex Data Master tasks in USE0 queue
  [15:0] COUNT — Number of Vertex Data Master tasks serviced by USE0
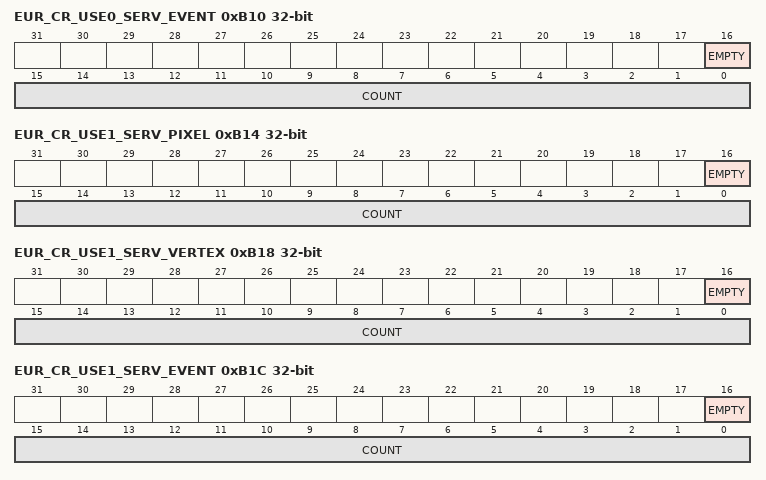
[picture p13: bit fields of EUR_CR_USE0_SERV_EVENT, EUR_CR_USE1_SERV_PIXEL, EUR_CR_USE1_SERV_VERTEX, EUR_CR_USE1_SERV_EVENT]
0xB10 EUR_CR_USE0_SERV_EVENT ro
  [16] EMPTY — No Event Data Master tasks in USE0 queue
  [15:0] COUNT — Number of Event Data Master tasks serviced by USE0
0xB14 EUR_CR_USE1_SERV_PIXEL ro
  [16] EMPTY — No Pixel Data Master tasks in USE1 queue
  [15:0] COUNT — Number of Pixel Data Master tasks serviced by USE1
0xB18 EUR_CR_USE1_SERV_VERTEX ro
  [16] EMPTY — No Vertex Data Master tasks in USE1 queue
  [15:0] COUNT — Number of Vertex Data Master tasks serviced by USE1
0xB1C EUR_CR_USE1_SERV_EVENT ro
  [16] EMPTY — No Event Data Master tasks in USE1 queue
  [15:0] COUNT — Number of Event Data Master tasks serviced by USE1
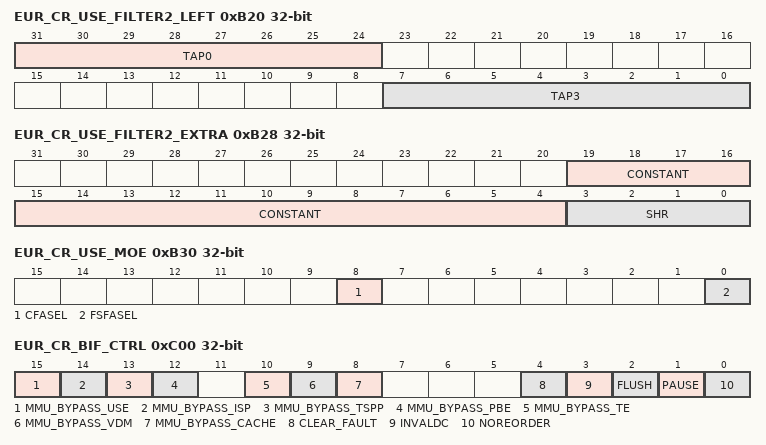
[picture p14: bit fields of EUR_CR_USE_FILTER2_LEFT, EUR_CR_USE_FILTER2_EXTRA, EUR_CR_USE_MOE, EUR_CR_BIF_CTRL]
0xB20 EUR_CR_USE_FILTER2_LEFT
  [31:24] TAP0 — FIRH instruction filter option, signed integer
  [7:0] TAP3 — FIRH instruction filter option, signed integer
0xB24 EUR_CR_USE_FILTER2_RIGHT
  [15:8] TAP6 — FIRH instruction filter option, signed integer
0xB28 EUR_CR_USE_FILTER2_EXTRA
  fields as EUR_CR_USE_FILTER0_EXTRA
0xB2C EUR_CR_PDS_PC_BASE ro
  [29:0] ADDRESS — PC base address
0xB30 EUR_CR_USE_MOE
  [8] CFASEL — Colour instruction format/address select
  [0] FSFASEL — EFO source format/address select
0xC00 EUR_CR_BIF_CTRL
  [15] MMU_BYPASS_USE — Setting to '1' bypasses the MMU for this requestor
  [14] MMU_BYPASS_ISP — Setting to '1' bypasses the MMU for this requestor
  [13] MMU_BYPASS_TSPP — Setting to '1' bypasses the MMU for this requestor
  [12] MMU_BYPASS_PBE — Setting to '1' bypasses the MMU for this requestor
  [10] MMU_BYPASS_TE — Setting to '1' bypasses the MMU for this requestor
  [9] MMU_BYPASS_VDM — Setting to '1' bypasses the MMU for this requestor
  [8] MMU_BYPASS_CACHE — Setting to '1' bypasses the MMU for this requestor
  [4] CLEAR_FAULT — Writing '1' clears the current fault in the EUR_CR_BIF_INT_STAT register
  [3] INVALDC — Writing '1' causes flushing of directory cache (and all other caches and tlbs)
  [2] FLUSH — Writing '1' causes flushing of address translation cache and all tlbs
  [1] PAUSE — Writing '1' causes bif operation to pause
  [0] NOREORDER — Writing '1' disables transaction re-ordering by signaling to the external SoC infrastructure to closely order the requests (Debug Only)
0xC04 EUR_CR_BIF_INT_STAT ro
  [14] PF_N_RW — Indicates whether the current fault is a page or R/W protection fault
  [13:0] FAULT — 1 bit per requestor indicating a page fault (only 1 can be set at once)
0xC08 EUR_CR_BIF_FAULT ro
  [27:12] ADDR — Page-aligned address causing page fault
0xC84 EUR_CR_BIF_DIR_LIST_BASE0
  [31:12] ADDR — Base address for Directory Cache updates
0xC90 EUR_CR_BIF_TA_REQ_BASE
  [27:20] ADDR — Base address for ta requestor - 256MB, 1MB aligned
0xCA8 EUR_CR_BIF_MEM_REQ_STAT ro
  [7:0] READS — Outstanding read requests in the memif
0xCAC EUR_CR_BIF_3D_REQ_BASE
  [27:20] ADDR — Base address for 3d requestors - 256MB, 1MB aligned
0xCB0 EUR_CR_BIF_ZLS_REQ_BASE
  [27:20] ADDR — Base address for zls requestor - 256MB, 1MB aligned
